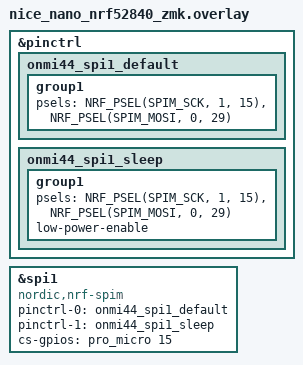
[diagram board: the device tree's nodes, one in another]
/*
 * nice!view on nice!nano for the Onmi44 v3.
 *
 * The stock nice_view_adapter uses SPI0 (P0.20 SCK / P0.17 MOSI) which
 * collides with the key matrix (COL3/COL2), so we put the display on SPI1
 * with free pro_micro pads instead:
 *   SCK  = A0 (P1.15)
 *   MOSI = A2 (P0.29)
 *   CS   = D15 (P1.13), active high (sharp,ls0xx)
 * No MISO: the ls0xx controller is write-only.
 */

#include <zephyr/dt-bindings/pinctrl/nrf-pinctrl.h>

&pinctrl {
    onmi44_spi1_default: onmi44_spi1_default {
        group1 {
            psels = <NRF_PSEL(SPIM_SCK, 1, 15)>,
                <NRF_PSEL(SPIM_MOSI, 0, 29)>;
        };
    };

    onmi44_spi1_sleep: onmi44_spi1_sleep {
        group1 {
            psels = <NRF_PSEL(SPIM_SCK, 1, 15)>,
                <NRF_PSEL(SPIM_MOSI, 0, 29)>;
            low-power-enable;
        };
    };
};

nice_view_spi: &spi1 {
    compatible = "nordic,nrf-spim";
    pinctrl-0 = <&onmi44_spi1_default>;
    pinctrl-1 = <&onmi44_spi1_sleep>;
    pinctrl-names = "default", "sleep";
    cs-gpios = <&pro_micro 15 GPIO_ACTIVE_HIGH>;
};
